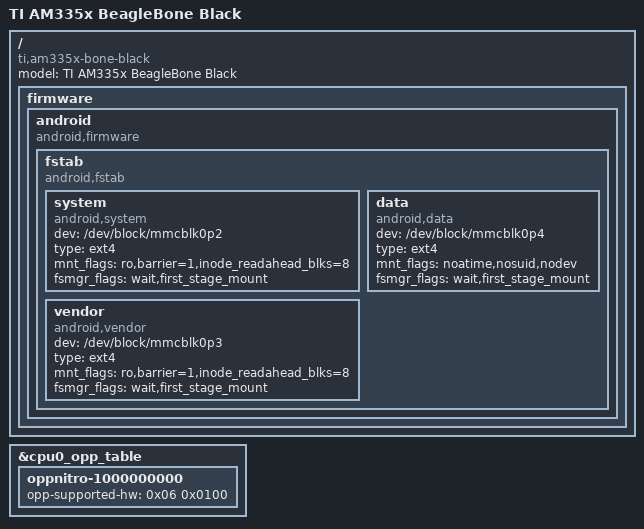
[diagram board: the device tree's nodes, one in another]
// SPDX-License-Identifier: GPL-2.0-only
/*
 * Copyright (C) 2012 Texas Instruments Incorporated - http://www.ti.com/
 */
/dts-v1/;

#include "am33xx.dtsi"
#include "am335x-bone-common.dtsi"
#include "am335x-boneblack-common.dtsi"

/ {
	model = "TI AM335x BeagleBone Black";
	compatible = "ti,am335x-bone-black", "ti,am335x-bone", "ti,am33xx";

	firmware {
			android {
			compatible = "android,firmware";
				fstab {
					compatible = "android,fstab";
					system {
						compatible = "android,system";
						dev = "/dev/block/mmcblk0p2";
						type = "ext4";
						mnt_flags = "ro,barrier=1,inode_readahead_blks=8";
						fsmgr_flags = "wait,first_stage_mount";
					};
					vendor {
						compatible = "android,vendor";
						dev = "/dev/block/mmcblk0p3";
						type = "ext4";
						mnt_flags = "ro,barrier=1,inode_readahead_blks=8";
						fsmgr_flags = "wait,first_stage_mount";
					};
					data {
						compatible = "android,data";
						dev = "/dev/block/mmcblk0p4";
						type = "ext4";
						mnt_flags = "noatime,nosuid,nodev";
						fsmgr_flags = "wait,first_stage_mount";
					};
				};
			};
		};
	
};

&cpu0_opp_table {
	/*
	 * All PG 2.0 silicon may not support 1GHz but some of the early
	 * BeagleBone Blacks have PG 2.0 silicon which is guaranteed
	 * to support 1GHz OPP so enable it for PG 2.0 on this board.
	 */
	oppnitro-1000000000 {
		opp-supported-hw = <0x06 0x0100>;
	};
};

